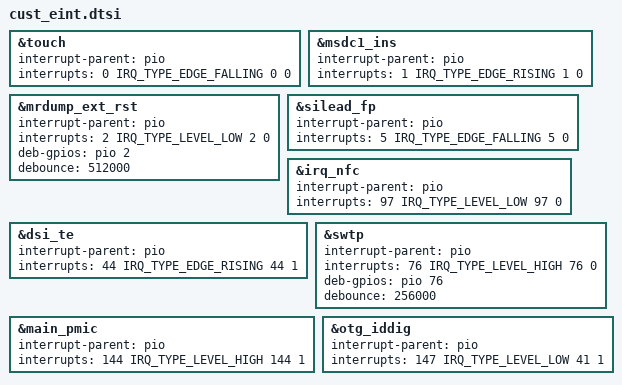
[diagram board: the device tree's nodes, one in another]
/*
 * Generated by MTK SP DrvGen Version: 3.5.160809 for MT6765.
 * 2026-08-02 08:23:43
 * Do Not Modify The File.
 * Copyright Mediatek Inc. (c) 2016.
*/

/*************************
 * EINT DTSI File
*************************/

#include <dt-bindings/interrupt-controller/irq.h>
#include <dt-bindings/interrupt-controller/arm-gic.h>

&touch {
	interrupt-parent = <&pio>;
	interrupts = <0 IRQ_TYPE_EDGE_FALLING 0 0>;
	status = "okay";
};

&msdc1_ins {
	interrupt-parent = <&pio>;
	interrupts = <1 IRQ_TYPE_EDGE_RISING 1 0>;
	status = "okay";
};

&mrdump_ext_rst {
	interrupt-parent = <&pio>;
	interrupts = <2 IRQ_TYPE_LEVEL_LOW 2 0>;
	deb-gpios = <&pio 2 0>;
	debounce = <512000>;
	status = "okay";
};

&silead_fp {
	interrupt-parent = <&pio>;
	interrupts = <5 IRQ_TYPE_EDGE_FALLING 5 0>;
	status = "okay";
};

&irq_nfc {
	interrupt-parent = <&pio>;
	interrupts = <10 IRQ_TYPE_LEVEL_HIGH 10 0>;
	status = "okay";
};

&dsi_te {
	interrupt-parent = <&pio>;
	interrupts = <44 IRQ_TYPE_EDGE_RISING 44 1>;
	status = "okay";
};

&swtp {
	interrupt-parent = <&pio>;
	interrupts = <76 IRQ_TYPE_LEVEL_HIGH 76 0>;
	deb-gpios = <&pio 76 0>;
	debounce = <256000>;
	status = "okay";
};

&irq_nfc {
	interrupt-parent = <&pio>;
	interrupts = <97 IRQ_TYPE_LEVEL_LOW 97 0>;
	status = "okay";
};

&main_pmic {
	interrupt-parent = <&pio>;
	interrupts = <144 IRQ_TYPE_LEVEL_HIGH 144 1>;
	status = "okay";
};

&otg_iddig {
	interrupt-parent = <&pio>;
	interrupts = <147 IRQ_TYPE_LEVEL_LOW 41 1>;
	status = "okay";
};

